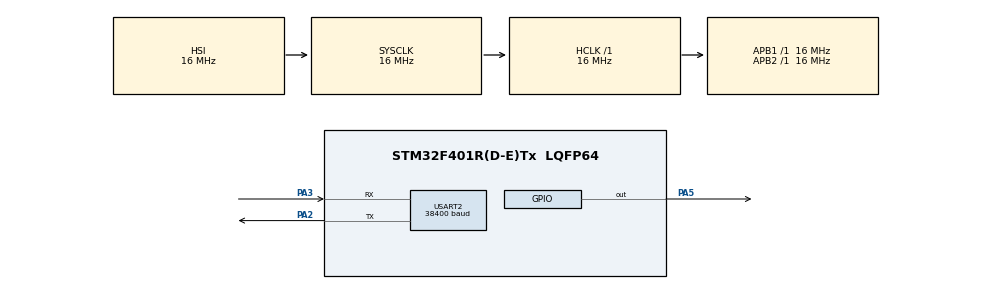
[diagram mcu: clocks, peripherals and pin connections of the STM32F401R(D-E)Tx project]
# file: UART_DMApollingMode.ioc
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Mcu.Family=STM32F4
RCC.CortexFreq_Value=16000000
Dma.USART2_TX.0.MemInc=DMA_MINC_ENABLE
Dma.USART2_TX.0.PeriphDataAlignment=DMA_PDATAALIGN_BYTE
USART2.BaudRate=38400
Dma.USART2_TX.0.FIFOMode=DMA_FIFOMODE_DISABLE
ProjectManager.StackSize=0x400
PA3.Mode=Asynchronous
Dma.USART2_TX.0.Priority=DMA_PRIORITY_LOW
ProjectManager.TargetToolchain=STM32CubeIDE
RCC.LSE_VALUE=32768
RCC.AHBFreq_Value=16000000
PA5.Signal=GPIO_Output
RCC.HSE_VALUE=25000000
board=custom
RCC.VCOOutputFreq_Value=192000000
RCC.APB2Freq_Value=16000000
Dma.USART2_TX.0.MemDataAlignment=DMA_MDATAALIGN_BYTE
Dma.USART2_TX.0.Direction=DMA_MEMORY_TO_PERIPH
Mcu.Name=STM32F401R(D-E)Tx
Dma.USART2_TX.0.Instance=DMA1_Stream6
PA2.Signal=USART2_TX
RCC.SYSCLKFreq_VALUE=16000000
Mcu.Package=LQFP64
Dma.USART2_TX.0.PeriphInc=DMA_PINC_DISABLE
USART2.VirtualMode=VM_ASYNC
ProjectManager.HeapSize=0x200
RCC.HSI_VALUE=16000000
Dma.USART2_TX.0.Mode=DMA_NORMAL
NVIC.PriorityGroup=NVIC_PRIORITYGROUP_4
PA2.Mode=Asynchronous
NVIC.DMA1_Stream6_IRQn=true\:0\:0\:false\:false\:true\:false\:true
Dma.Request0=USART2_TX
RCC.APB1Freq_Value=16000000
PA3.Signal=USART2_RX

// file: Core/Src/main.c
/* USER CODE BEGIN Header */
/**
  ******************************************************************************
  * @file           : main.c
  * @brief          : Main program body
  ******************************************************************************
  * @attention
  *
  * <h2><center>&copy; Copyright (c) 2021 STMicroelectronics.
  * All rights reserved.</center></h2>
  *
  * This software component is licensed by ST under BSD 3-Clause license,
  * the "License"; You may not use this file except in compliance with the
  * License. You may obtain a copy of the License at:
  *                        opensource.org/licenses/BSD-3-Clause
  *
  ******************************************************************************
  */
/* USER CODE END Header */
#include "main.h"

UART_HandleTypeDef huart2;
DMA_HandleTypeDef hdma_usart2_tx;

/* USER CODE BEGIN PV */
char *msg = "Hello STM32 Lovers! This message is transferred in DMA Mode.\r\n";
/* USER CODE END PV */

void SystemClock_Config(void);
static void MX_GPIO_Init(void);
static void MX_DMA_Init(void);
static void MX_USART2_UART_Init(void);

int main(void)
{

  /* MCU Configuration--------------------------------------------------------*/

  /* Reset of all peripherals, Initializes the Flash interface and the Systick. */
  HAL_Init();

  /* Configure the system clock */
  SystemClock_Config();

  /* Initialize all configured peripherals */
  MX_GPIO_Init();
  MX_DMA_Init();
  MX_USART2_UART_Init();

  /* USER CODE BEGIN 2 */
  HAL_DMA_Start(&hdma_usart2_tx,  (uint32_t)msg,  (uint32_t)&huart2.Instance->DR, strlen(msg));
  /*
  dopo aver configurato il DMA in polling mode, avviamo il trasferimento abilitando l' UART in DMA mode

  #define  USART_CR3_DMAT                      0x0080U

  Bit 7 DMAT: DMA enable transmitter
  This bit is set/reset by software
  1: DMA mode is enabled for transmission.
  0: DMA mode is disabled for transmission.
  */
  huart2.Instance->CR3 |= USART_CR3_DMAT;

  //Wait for transfer complete
  HAL_DMA_PollForTransfer(&hdma_usart2_tx, HAL_DMA_FULL_TRANSFER, HAL_MAX_DELAY);
  //Disable UART DMA mode
  huart2.Instance->CR3 &= ~USART_CR3_DMAT;
  //Turn LD2 ON
  HAL_GPIO_WritePin(GPIOA, GPIO_PIN_5, GPIO_PIN_SET);
  /* USER CODE END 2 */

  /* Infinite loop */
  while (1)
  {

  }
}

void SystemClock_Config(void)
{
  RCC_OscInitTypeDef RCC_OscInitStruct = {0};
  RCC_ClkInitTypeDef RCC_ClkInitStruct = {0};

  /** Configure the main internal regulator output voltage
  */
  __HAL_RCC_PWR_CLK_ENABLE();
  __HAL_PWR_VOLTAGESCALING_CONFIG(PWR_REGULATOR_VOLTAGE_SCALE2);
  /** Initializes the RCC Oscillators according to the specified parameters
  * in the RCC_OscInitTypeDef structure.
  */
  RCC_OscInitStruct.OscillatorType = RCC_OSCILLATORTYPE_HSI;
  RCC_OscInitStruct.HSIState = RCC_HSI_ON;
  RCC_OscInitStruct.HSICalibrationValue = RCC_HSICALIBRATION_DEFAULT;
  RCC_OscInitStruct.PLL.PLLState = RCC_PLL_NONE;
  if (HAL_RCC_OscConfig(&RCC_OscInitStruct) != HAL_OK)
  {
    Error_Handler();
  }
  /** Initializes the CPU, AHB and APB buses clocks
  */
  RCC_ClkInitStruct.ClockType = RCC_CLOCKTYPE_HCLK|RCC_CLOCKTYPE_SYSCLK
                              |RCC_CLOCKTYPE_PCLK1|RCC_CLOCKTYPE_PCLK2;
  RCC_ClkInitStruct.SYSCLKSource = RCC_SYSCLKSOURCE_HSI;
  RCC_ClkInitStruct.AHBCLKDivider = RCC_SYSCLK_DIV1;
  RCC_ClkInitStruct.APB1CLKDivider = RCC_HCLK_DIV1;
  RCC_ClkInitStruct.APB2CLKDivider = RCC_HCLK_DIV1;

  if (HAL_RCC_ClockConfig(&RCC_ClkInitStruct, FLASH_LATENCY_0) != HAL_OK)
  {
    Error_Handler();
  }
}

static void MX_USART2_UART_Init(void)
{

  huart2.Instance = USART2;
  huart2.Init.BaudRate = 38400;
  huart2.Init.WordLength = UART_WORDLENGTH_8B;
  huart2.Init.StopBits = UART_STOPBITS_1;
  huart2.Init.Parity = UART_PARITY_NONE;
  huart2.Init.Mode = UART_MODE_TX_RX;
  huart2.Init.HwFlowCtl = UART_HWCONTROL_NONE;
  huart2.Init.OverSampling = UART_OVERSAMPLING_16;
  if (HAL_UART_Init(&huart2) != HAL_OK)
  {
    Error_Handler();
  }

}

static void MX_DMA_Init(void)
{

  /* DMA controller clock enable */
  __HAL_RCC_DMA1_CLK_ENABLE();

  /* DMA interrupt init */
  /* DMA1_Stream6_IRQn interrupt configuration */
  HAL_NVIC_SetPriority(DMA1_Stream6_IRQn, 0, 0);
  HAL_NVIC_EnableIRQ(DMA1_Stream6_IRQn);

}

static void MX_GPIO_Init(void)
{
  GPIO_InitTypeDef GPIO_InitStruct = {0};

  /* GPIO Ports Clock Enable */
  __HAL_RCC_GPIOA_CLK_ENABLE();

  /*Configure GPIO pin Output Level */
  HAL_GPIO_WritePin(GPIOA, GPIO_PIN_5, GPIO_PIN_RESET);

  /*Configure GPIO pin : PA5 */
  GPIO_InitStruct.Pin = GPIO_PIN_5;
  GPIO_InitStruct.Mode = GPIO_MODE_OUTPUT_PP;
  GPIO_InitStruct.Pull = GPIO_NOPULL;
  GPIO_InitStruct.Speed = GPIO_SPEED_FREQ_LOW;
  HAL_GPIO_Init(GPIOA, &GPIO_InitStruct);

}

void Error_Handler(void)
{
  __disable_irq();
  while (1)
  {
  }
}

/************************ (C) COPYRIGHT STMicroelectronics *****END OF FILE****/
